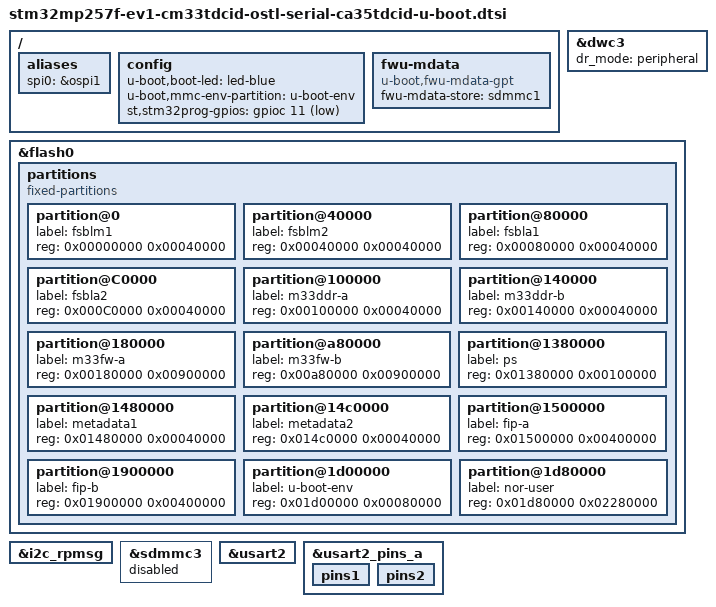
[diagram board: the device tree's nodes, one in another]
// SPDX-License-Identifier: (GPL-2.0-only OR BSD-3-Clause)
/*
 * Copyright (C) STMicroelectronics 2021 - All Rights Reserved
 */

#include "stm32mp25-u-boot.dtsi"

/ {
	aliases {
		spi0 = &ospi1;
	};

	config {
		u-boot,boot-led = "led-blue";
		u-boot,mmc-env-partition = "u-boot-env";
		st,stm32prog-gpios = <&gpioc 11 (GPIO_ACTIVE_LOW | GPIO_PULL_UP)>;
	};

	fwu-mdata {
		compatible = "u-boot,fwu-mdata-gpt";
		fwu-mdata-store = <&sdmmc1>;
	};
};

&dwc3 {
	dr_mode = "peripheral";
	/delete-node/ port;
};

&flash0 {
	partitions {
		compatible = "fixed-partitions";
		#address-cells = <1>;
		#size-cells = <1>;

		partition@0 {
			label = "fsblm1";
			reg = <0x00000000 0x00040000>;
		};
		partition@40000 {
			label = "fsblm2";
			reg = <0x00040000 0x00040000>;
		};
		partition@80000 {
			label = "fsbla1";
			reg = <0x00080000 0x00040000>;
		};
		partition@C0000 {
			label = "fsbla2";
			reg = <0x000C0000 0x00040000>;
		};
		partition@100000 {
			label = "m33ddr-a";
			reg = <0x00100000 0x00040000>;
		};
		partition@140000 {
			label = "m33ddr-b";
			reg = <0x00140000 0x00040000>;
		};
		partition@180000 {
			label = "m33fw-a";
			reg = <0x00180000 0x00900000>;
		};
		partition@a80000 {
			label = "m33fw-b";
			reg = <0x00a80000 0x00900000>;
		};
		partition@1380000 {
			label = "ps";
			reg = <0x01380000 0x00100000>;
		};
		partition@1480000 {
			label = "metadata1";
			reg = <0x01480000 0x00040000>;
		};
		partition@14c0000 {
			label = "metadata2";
			reg = <0x014c0000 0x00040000>;
		};
		partition@1500000 {
			label = "fip-a";
			reg = <0x01500000 0x00400000>;
		};
		partition@1900000 {
			label = "fip-b";
			reg = <0x01900000 0x00400000>;
		};
		partition@1d00000 {
			label = "u-boot-env";
			reg = <0x01d00000 0x00080000>;
		};
		partition@1d80000 {
			label = "nor-user";
			reg = <0x01d80000 0x02280000>;
		};
	};
};

&i2c_rpmsg {
	/delete-node/ typec@35;
};

&sdmmc3 {
	status = "disabled";
};

&usart2 {
	bootph-all;
};

&usart2_pins_a {
	bootph-all;
	pins1 {
		bootph-all;
	};
	pins2 {
		bootph-all;
	};
};
